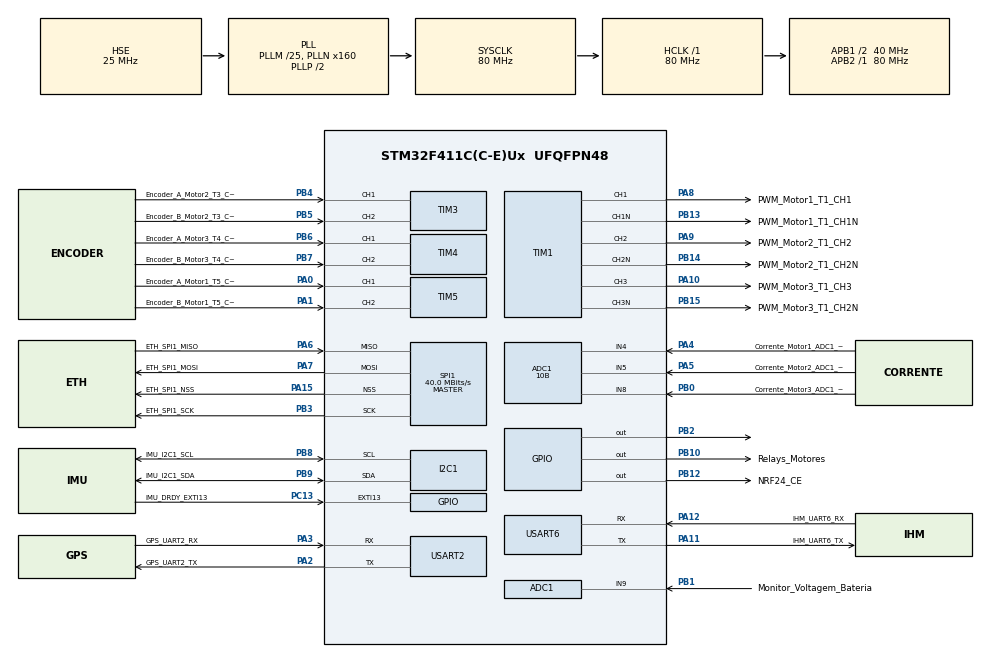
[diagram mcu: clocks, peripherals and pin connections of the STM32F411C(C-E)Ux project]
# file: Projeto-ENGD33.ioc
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ADC1.Channel-0\#ChannelRegularConversion=ADC_CHANNEL_4
ADC1.NbrOfConversion=1
ADC1.NbrOfConversionFlag=1
ADC1.Rank-0\#ChannelRegularConversion=1
ADC1.Resolution=ADC_RESOLUTION_10B
ADC1.SamplingTime-0\#ChannelRegularConversion=ADC_SAMPLETIME_3CYCLES
ADC1.master=1
FATFS._MAX_SS=4096
FREERTOS.Tasks01=defaultTask,24,128,StartDefaultTask,Default,NULL,Dynamic,NULL,NULL
FREERTOS.configUSE_NEWLIB_REENTRANT=1
Mcu.Family=STM32F4
Mcu.Name=STM32F411C(C-E)Ux
Mcu.Package=UFQFPN48
NVIC.EXTI15_10_IRQn=true\:5\:0\:false\:false\:true\:true\:true\:true\:true
NVIC.I2C1_ER_IRQn=true\:5\:0\:false\:false\:true\:true\:true\:true\:true
NVIC.I2C1_EV_IRQn=true\:5\:0\:false\:false\:true\:true\:true\:true\:true
NVIC.PriorityGroup=NVIC_PRIORITYGROUP_4
NVIC.SPI1_IRQn=true\:5\:0\:false\:false\:true\:true\:true\:true\:true
NVIC.TIM2_IRQn=true\:15\:0\:false\:false\:true\:false\:false\:true\:true
NVIC.TimeBase=TIM2_IRQn
NVIC.TimeBaseIP=TIM2
NVIC.USART2_IRQn=true\:5\:0\:false\:false\:true\:true\:true\:true\:true
NVIC.USART6_IRQn=true\:5\:0\:false\:false\:true\:true\:true\:true\:true
PA0-WKUP.GPIO_Label=Encoder_A_Motor1_T5_CH1
PA0-WKUP.Signal=S_TIM5_CH1
PA1.GPIO_Label=Encoder_B_Motor1_T5_CH2
PA1.Signal=S_TIM5_CH2
PA10.GPIO_Label=PWM_Motor3_T1_CH3
PA10.Signal=S_TIM1_CH3
PA11.GPIO_Label=IHM_UART6_TX
PA11.Mode=Asynchronous
PA11.Signal=USART6_TX
PA12.GPIO_Label=IHM_UART6_RX
PA12.Mode=Asynchronous
PA12.Signal=USART6_RX
PA13.Signal=SYS_JTMS-SWDIO
PA14.Signal=SYS_JTCK-SWCLK
PA15.GPIO_Label=ETH_SPI1_NSS
PA15.Mode=NSS_Signal_Hard_Output
PA15.Signal=SPI1_NSS
PA2.GPIO_Label=GPS_UART2_TX
PA2.Mode=Asynchronous
PA2.Signal=USART2_TX
PA3.GPIO_Label=GPS_UART2_RX
PA3.Mode=Asynchronous
PA3.Signal=USART2_RX
PA4.GPIO_Label=Corrente_Motor1_ADC1_IN4
PA4.Signal=ADCx_IN4
PA5.GPIO_Label=Corrente_Motor2_ADC1_IN5
PA5.Signal=ADCx_IN5
PA6.GPIO_Label=ETH_SPI1_MISO
PA6.Mode=Full_Duplex_Master
PA6.Signal=SPI1_MISO
PA7.GPIO_Label=ETH_SPI1_MOSI
PA7.Mode=Full_Duplex_Master
PA7.Signal=SPI1_MOSI
PA8.GPIO_Label=PWM_Motor1_T1_CH1
PA8.Signal=S_TIM1_CH1
PA9.GPIO_Label=PWM_Motor2_T1_CH2
PA9.Signal=S_TIM1_CH2
PB0.GPIO_Label=Corrente_Motor3_ADC1_IN8
PB0.Signal=ADCx_IN8
PB1.GPIO_Label=Monitor_Voltagem_Bateria
PB1.Signal=ADCx_IN9
PB10.GPIO_Label=Relays_Motores
PB10.Signal=GPIO_Output
PB12.GPIO_Label=NRF24_CE
PB12.GPIO_Speed=GPIO_SPEED_FREQ_VERY_HIGH
PB12.Signal=GPIO_Output
PB13.GPIO_Label=PWM_Motor1_T1_CH1N
PB13.Mode=PWM Generation1 CH1 CH1N
PB13.Signal=TIM1_CH1N
PB14.GPIO_Label=PWM_Motor2_T1_CH2N
PB14.Mode=PWM Generation2 CH2 CH2N
PB14.Signal=TIM1_CH2N
PB15.GPIO_Label=PWM_Motor3_T1_CH2N
PB15.Mode=PWM Generation3 CH3 CH3N
PB15.Signal=TIM1_CH3N
PB2.Signal=GPIO_Output
PB3.GPIO_Label=ETH_SPI1_SCK
PB3.Mode=Full_Duplex_Master
PB3.Signal=SPI1_SCK
PB4.GPIO_Label=Encoder_A_Motor2_T3_CH1
PB4.Signal=S_TIM3_CH1
PB5.GPIO_Label=Encoder_B_Motor2_T3_CH2
PB5.Signal=S_TIM3_CH2
PB6.GPIO_Label=Encoder_A_Motor3_T4_CH1
PB6.Signal=S_TIM4_CH1
PB7.GPIO_Label=Encoder_B_Motor3_T4_CH2
PB7.Signal=S_TIM4_CH2
PB8.GPIO_Label=IMU_I2C1_SCL
PB8.Mode=I2C
PB8.Signal=I2C1_SCL
PB9.GPIO_Label=IMU_I2C1_SDA
PB9.Mode=I2C
PB9.Signal=I2C1_SDA
PC13-ANTI_TAMP.GPIO_Label=IMU_DRDY_EXTI13
PC13-ANTI_TAMP.Signal=GPXTI13
PC14-OSC32_IN.GPIO_Label=Osc_32k768Hz_In
PC14-OSC32_IN.Mode=LSE-External-Oscillator
PC14-OSC32_IN.Signal=RCC_OSC32_IN
PC15-OSC32_OUT.GPIO_Label=Osc_32k768Hz_Out
PC15-OSC32_OUT.Mode=LSE-External-Oscillator
PC15-OSC32_OUT.Signal=RCC_OSC32_OUT
PH0\ -\ OSC_IN.GPIO_Label=Osc_25MHz_In
PH0\ -\ OSC_IN.Mode=HSE-External-Oscillator
PH0\ -\ OSC_IN.Signal=RCC_OSC_IN
PH1\ -\ OSC_OUT.GPIO_Label=Osc_25MHz_Out
PH1\ -\ OSC_OUT.Mode=HSE-External-Oscillator
PH1\ -\ OSC_OUT.Signal=RCC_OSC_OUT
ProjectManager.HeapSize=0x200
ProjectManager.StackSize=0x400
ProjectManager.TargetToolchain=STM32CubeIDE
RCC.48MHZClocksFreq_Value=40000000
RCC.AHBFreq_Value=80000000
RCC.APB1CLKDivider=RCC_HCLK_DIV2
RCC.APB1Freq_Value=40000000
RCC.APB1TimFreq_Value=80000000
RCC.APB2Freq_Value=80000000
RCC.APB2TimFreq_Value=80000000
RCC.CortexFreq_Value=80000000
RCC.HCLKFreq_Value=80000000
RCC.HSE_VALUE=25000000
RCC.HSI_VALUE=16000000
RCC.PLLM=25
RCC.PLLN=160
RCC.PLLSourceVirtual=RCC_PLLSOURCE_HSE
RCC.RCC_RTC_Clock_Source=RCC_RTCCLKSOURCE_LSE
RCC.RCC_RTC_Clock_SourceVirtual=RCC_RTCCLKSOURCE_LSE
RCC.SYSCLKFreq_VALUE=80000000
RCC.SYSCLKSource=RCC_SYSCLKSOURCE_PLLCLK
RCC.VCOOutputFreq_Value=160000000
SH.ADCx_IN4.0=ADC1_IN4,IN4
SH.ADCx_IN5.0=ADC1_IN5,IN5
SH.ADCx_IN8.0=ADC1_IN8,IN8
SH.ADCx_IN9.0=ADC1_IN9,IN9
SH.S_TIM1_CH1.0=TIM1_CH1,PWM Generation1 CH1 CH1N
SH.S_TIM1_CH2.0=TIM1_CH2,PWM Generation2 CH2 CH2N
SH.S_TIM1_CH3.0=TIM1_CH3,PWM Generation3 CH3 CH3N
SH.S_TIM3_CH1.0=TIM3_CH1,Encoder_Interface
SH.S_TIM3_CH2.0=TIM3_CH2,Encoder_Interface
SH.S_TIM4_CH1.0=TIM4_CH1,Encoder_Interface
SH.S_TIM4_CH2.0=TIM4_CH2,Encoder_Interface
SH.S_TIM5_CH1.0=TIM5_CH1,Encoder_Interface
SH.S_TIM5_CH2.0=TIM5_CH2,Encoder_Interface
SPI1.CalculateBaudRate=40.0 MBits/s
SPI1.Direction=SPI_DIRECTION_2LINES
SPI1.Mode=SPI_MODE_MASTER
SPI1.VirtualNSS=VM_NSSHARD
SPI1.VirtualType=VM_MASTER
TIM1.Channel-PWM\ Generation1\ CH1\ CH1N=TIM_CHANNEL_1
TIM1.Channel-PWM\ Generation2\ CH2\ CH2N=TIM_CHANNEL_2
TIM1.Channel-PWM\ Generation3\ CH3\ CH3N=TIM_CHANNEL_3
USART2.VirtualMode=VM_ASYNC
USART6.VirtualMode=VM_ASYNC
VP_ADC1_TempSens_Input.Mode=IN-TempSens
VP_FATFS_VS_Generic.Mode=User_defined
VP_FREERTOS_VS_CMSIS_V2.Mode=CMSIS_V2
VP_RTC_VS_RTC_Activate.Mode=RTC_Enabled
VP_RTC_VS_RTC_Calendar.Mode=RTC_Calendar
VP_SYS_VS_tim2.Mode=TIM2
VP_TIM1_VS_ClockSourceINT.Mode=Internal
board=custom

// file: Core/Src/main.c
/* USER CODE BEGIN Header */
/**
  ******************************************************************************
  * @file           : main.c
  * @brief          : Main program body
  ******************************************************************************
  * @attention
  *
  * Copyright (c) 2025 STMicroelectronics.
  * All rights reserved.
  *
  * This software is licensed under terms that can be found in the LICENSE file
  * in the root directory of this software component.
  * If no LICENSE file comes with this software, it is provided AS-IS.
  *
  ******************************************************************************
  */
/* USER CODE END Header */
#include "main.h"
#include "cmsis_os.h"
#include "fatfs.h"
#include "datalogger.h"

/* USER CODE BEGIN Includes */

#include "GY-87.h"
#include <math.h>
// Biblioteca necessária para o snprintf:
#include <stdio.h>
// FreeRTOS
#include "FreeRTOS.h"
#include "task.h"
#include "queue.h"
// #include <stdbool.h>

/* USER CODE END Includes */

ADC_HandleTypeDef hadc1;

I2C_HandleTypeDef hi2c1;

RTC_HandleTypeDef hrtc;

SPI_HandleTypeDef hspi1;

TIM_HandleTypeDef htim1;
TIM_HandleTypeDef htim3;
TIM_HandleTypeDef htim4;
TIM_HandleTypeDef htim5;

UART_HandleTypeDef huart2;
UART_HandleTypeDef huart6;

/* Definitions for defaultTask */
osThreadId_t defaultTaskHandle;
const osThreadAttr_t defaultTask_attributes = {
  .name = "defaultTask",
  .stack_size = 128 * 4,
  .priority = (osPriority_t) osPriorityNormal,
};

void SystemClock_Config(void);
static void MX_GPIO_Init(void);
static void MX_DMA_Init(void);
static void MX_RTC_Init(void);
static void MX_ADC1_Init(void);
static void MX_I2C1_Init(void);
static void MX_SPI1_Init(void);
static void MX_TIM1_Init(void);
static void MX_TIM3_Init(void);
static void MX_TIM4_Init(void);
static void MX_TIM5_Init(void);
static void MX_USART2_UART_Init(void);
static void MX_USART6_UART_Init(void);
void StartDefaultTask(void *argument);

/* USER CODE BEGIN PFP */
void HAL_GPIO_EXTI_Callback(uint16_t GPIO_Pin);
void HAL_TIM_PeriodElapsedCallback(TIM_HandleTypeDef* htim);
// void Calibrate_ADC_Converter(void);
void Start_Encoders(void);
void Stop_Encoders(void);
void Start_PWMs(void);
void Stop_PWMs(void);
void Reset_Relays_Motors(void);
void Set_Relays_Motors(void);
void Reset_NRF24_CE(void);
void Set_NRF24_CE(void);
void Configure_Compass(void);
int  Get_Direction_Rotation_Wheel_1(void);
int  Get_Direction_Rotation_Wheel_2(void);
int  Get_Direction_Rotation_Wheel_3(void);
float Read_Speed_Wheel_1(void);
float Read_Speed_Wheel_2(void);
float Read_Speed_Wheel_3(void);
float Read_Current_Motor_1(void);
float Read_Current_Motor_2(void);
float Read_Current_Motor_3(void);
void Write_Control_Signal_Motor_1(float Value);
void Write_Control_Signal_Motor_2(float Value);
void Write_Control_Signal_Motor_3(float Value);
float Read_Voltage_Battery(void);
float Read_Temperature_uP(void);
// Tasks do FreeRTOS
void Task_Controle(void *argument);
void Task_SDCard(void *argument);

// Funções de Hardware e Mock
TempoRTC_t Hardware_LerRTC(void);
Sensores_t Mock_LerSensores(void);

/* USER CODE END PFP */

int main(void)
{

  /* MCU Configuration--------------------------------------------------------*/

  /* Reset of all peripherals, Initializes the Flash interface and the Systick. */
  HAL_Init();

  /* Configure the system clock */
  SystemClock_Config();

  /* Initialize all configured peripherals */
  MX_GPIO_Init();
  MX_DMA_Init();
  MX_RTC_Init();
  MX_ADC1_Init();
  MX_I2C1_Init();
  MX_SPI1_Init();
  MX_TIM1_Init();
  MX_TIM3_Init();
  MX_TIM4_Init();
  MX_TIM5_Init();
  MX_USART2_UART_Init();
  MX_USART6_UART_Init();
  MX_FATFS_Init();
  /* USER CODE BEGIN 2 */
  Datalogger_Init();
  /* USER CODE END 2 */

  /* Init scheduler */
  osKernelInitialize();

  /* Create the thread(s) */
  /* creation of defaultTask */
  defaultTaskHandle = osThreadNew(StartDefaultTask, NULL, &defaultTask_attributes);

  /* Start scheduler */
  osKernelStart();

  /* We should never get here as control is now taken by the scheduler */

  /* Infinite loop */
  while (1)
  {

  }
}

void SystemClock_Config(void)
{
  RCC_OscInitTypeDef RCC_OscInitStruct = {0};
  RCC_ClkInitTypeDef RCC_ClkInitStruct = {0};

  /** Configure the main internal regulator output voltage
  */
  __HAL_RCC_PWR_CLK_ENABLE();
  __HAL_PWR_VOLTAGESCALING_CONFIG(PWR_REGULATOR_VOLTAGE_SCALE1);

  /** Initializes the RCC Oscillators according to the specified parameters
  * in the RCC_OscInitTypeDef structure.
  */
  RCC_OscInitStruct.OscillatorType = RCC_OSCILLATORTYPE_HSE|RCC_OSCILLATORTYPE_LSE;
  RCC_OscInitStruct.HSEState = RCC_HSE_ON;
  RCC_OscInitStruct.LSEState = RCC_LSE_ON;
  RCC_OscInitStruct.PLL.PLLState = RCC_PLL_ON;
  RCC_OscInitStruct.PLL.PLLSource = RCC_PLLSOURCE_HSE;
  RCC_OscInitStruct.PLL.PLLM = 25;
  RCC_OscInitStruct.PLL.PLLN = 160;
  RCC_OscInitStruct.PLL.PLLP = RCC_PLLP_DIV2;
  RCC_OscInitStruct.PLL.PLLQ = 4;
  if (HAL_RCC_OscConfig(&RCC_OscInitStruct) != HAL_OK)
  {
    Error_Handler();
  }

  /** Initializes the CPU, AHB and APB buses clocks
  */
  RCC_ClkInitStruct.ClockType = RCC_CLOCKTYPE_HCLK|RCC_CLOCKTYPE_SYSCLK
                              |RCC_CLOCKTYPE_PCLK1|RCC_CLOCKTYPE_PCLK2;
  RCC_ClkInitStruct.SYSCLKSource = RCC_SYSCLKSOURCE_PLLCLK;
  RCC_ClkInitStruct.AHBCLKDivider = RCC_SYSCLK_DIV1;
  RCC_ClkInitStruct.APB1CLKDivider = RCC_HCLK_DIV2;
  RCC_ClkInitStruct.APB2CLKDivider = RCC_HCLK_DIV1;

  if (HAL_RCC_ClockConfig(&RCC_ClkInitStruct, FLASH_LATENCY_2) != HAL_OK)
  {
    Error_Handler();
  }
}

static void MX_ADC1_Init(void)
{

  ADC_ChannelConfTypeDef sConfig = {0};

  /** Configure the global features of the ADC (Clock, Resolution, Data Alignment and number of conversion)
  */
  hadc1.Instance = ADC1;
  hadc1.Init.ClockPrescaler = ADC_CLOCK_SYNC_PCLK_DIV4;
  hadc1.Init.Resolution = ADC_RESOLUTION_10B;
  hadc1.Init.ScanConvMode = DISABLE;
  hadc1.Init.ContinuousConvMode = DISABLE;
  hadc1.Init.DiscontinuousConvMode = DISABLE;
  hadc1.Init.ExternalTrigConvEdge = ADC_EXTERNALTRIGCONVEDGE_NONE;
  hadc1.Init.ExternalTrigConv = ADC_SOFTWARE_START;
  hadc1.Init.DataAlign = ADC_DATAALIGN_RIGHT;
  hadc1.Init.NbrOfConversion = 1;
  hadc1.Init.DMAContinuousRequests = DISABLE;
  hadc1.Init.EOCSelection = ADC_EOC_SINGLE_CONV;
  if (HAL_ADC_Init(&hadc1) != HAL_OK)
  {
    Error_Handler();
  }

  /** Configure for the selected ADC regular channel its corresponding rank in the sequencer and its sample time.
  */
  sConfig.Channel = ADC_CHANNEL_4;
  sConfig.Rank = 1;
  sConfig.SamplingTime = ADC_SAMPLETIME_3CYCLES;
  if (HAL_ADC_ConfigChannel(&hadc1, &sConfig) != HAL_OK)
  {
    Error_Handler();
  }

}

static void MX_I2C1_Init(void)
{

  hi2c1.Instance = I2C1;
  hi2c1.Init.ClockSpeed = 400000;
  hi2c1.Init.DutyCycle = I2C_DUTYCYCLE_2;
  hi2c1.Init.OwnAddress1 = 0;
  hi2c1.Init.AddressingMode = I2C_ADDRESSINGMODE_7BIT;
  hi2c1.Init.DualAddressMode = I2C_DUALADDRESS_DISABLE;
  hi2c1.Init.OwnAddress2 = 0;
  hi2c1.Init.GeneralCallMode = I2C_GENERALCALL_DISABLE;
  hi2c1.Init.NoStretchMode = I2C_NOSTRETCH_DISABLE;
  if (HAL_I2C_Init(&hi2c1) != HAL_OK)
  {
    Error_Handler();
  }

}

static void MX_RTC_Init(void)
{

  RTC_TimeTypeDef sTime = {0};
  RTC_DateTypeDef sDate = {0};

  /** Initialize RTC Only
  */
  hrtc.Instance = RTC;
  hrtc.Init.HourFormat = RTC_HOURFORMAT_24;
  hrtc.Init.AsynchPrediv = 127;
  hrtc.Init.SynchPrediv = 255;
  hrtc.Init.OutPut = RTC_OUTPUT_DISABLE;
  hrtc.Init.OutPutPolarity = RTC_OUTPUT_POLARITY_HIGH;
  hrtc.Init.OutPutType = RTC_OUTPUT_TYPE_OPENDRAIN;
  if (HAL_RTC_Init(&hrtc) != HAL_OK)
  {
    Error_Handler();
  }

  /* USER CODE BEGIN Check_RTC_BKUP */

  /* Se a assinatura já estiver gravada no registrador de backup, o RTC
   * sobreviveu ao reset e já tem hora/data válidas: não sobrescrever. */
  if (HAL_RTCEx_BKUPRead(&hrtc, RTC_BKP_DR1) == 0x1234)
  {
    return;
  }

  /* USER CODE END Check_RTC_BKUP */

  /** Initialize RTC and set the Time and Date
  */
  sTime.Hours = 14;
  sTime.Minutes = 30;
  sTime.Seconds = 0;
  sTime.DayLightSaving = RTC_DAYLIGHTSAVING_NONE;
  sTime.StoreOperation = RTC_STOREOPERATION_RESET;
  if (HAL_RTC_SetTime(&hrtc, &sTime, RTC_FORMAT_BIN) != HAL_OK)
  {
    Error_Handler();
  }
  sDate.WeekDay = RTC_WEEKDAY_TUESDAY;
  sDate.Month = RTC_MONTH_JULY;
  sDate.Date = 7;
  sDate.Year = 26;

  if (HAL_RTC_SetDate(&hrtc, &sDate, RTC_FORMAT_BIN) != HAL_OK)
  {
    Error_Handler();
  }
  /* USER CODE BEGIN RTC_Init 2 */

  /* Marca no registrador de backup que a hora/data já foi configurada,
   * para não ser resetada nos próximos boots. */
  HAL_RTCEx_BKUPWrite(&hrtc, RTC_BKP_DR1, 0x1234);

  /* USER CODE END RTC_Init 2 */

}

static void MX_SPI1_Init(void)
{

  /* SPI1 parameter configuration*/
  hspi1.Instance = SPI1;
  hspi1.Init.Mode = SPI_MODE_MASTER;
  hspi1.Init.Direction = SPI_DIRECTION_2LINES;
  hspi1.Init.DataSize = SPI_DATASIZE_8BIT;
  hspi1.Init.CLKPolarity = SPI_POLARITY_LOW;
  hspi1.Init.CLKPhase = SPI_PHASE_1EDGE;
  hspi1.Init.NSS = SPI_NSS_HARD_OUTPUT;
  hspi1.Init.BaudRatePrescaler = SPI_BAUDRATEPRESCALER_2;
  hspi1.Init.FirstBit = SPI_FIRSTBIT_MSB;
  hspi1.Init.TIMode = SPI_TIMODE_DISABLE;
  hspi1.Init.CRCCalculation = SPI_CRCCALCULATION_DISABLE;
  hspi1.Init.CRCPolynomial = 10;
  if (HAL_SPI_Init(&hspi1) != HAL_OK)
  {
    Error_Handler();
  }

}

static void MX_TIM1_Init(void)
{

  TIM_ClockConfigTypeDef sClockSourceConfig = {0};
  TIM_MasterConfigTypeDef sMasterConfig = {0};
  TIM_OC_InitTypeDef sConfigOC = {0};
  TIM_BreakDeadTimeConfigTypeDef sBreakDeadTimeConfig = {0};

  htim1.Instance = TIM1;
  htim1.Init.Prescaler = 0;
  htim1.Init.CounterMode = TIM_COUNTERMODE_UP;
  htim1.Init.Period = 65535;
  htim1.Init.ClockDivision = TIM_CLOCKDIVISION_DIV1;
  htim1.Init.RepetitionCounter = 0;
  htim1.Init.AutoReloadPreload = TIM_AUTORELOAD_PRELOAD_DISABLE;
  if (HAL_TIM_Base_Init(&htim1) != HAL_OK)
  {
    Error_Handler();
  }
  sClockSourceConfig.ClockSource = TIM_CLOCKSOURCE_INTERNAL;
  if (HAL_TIM_ConfigClockSource(&htim1, &sClockSourceConfig) != HAL_OK)
  {
    Error_Handler();
  }
  if (HAL_TIM_PWM_Init(&htim1) != HAL_OK)
  {
    Error_Handler();
  }
  sMasterConfig.MasterOutputTrigger = TIM_TRGO_RESET;
  sMasterConfig.MasterSlaveMode = TIM_MASTERSLAVEMODE_DISABLE;
  if (HAL_TIMEx_MasterConfigSynchronization(&htim1, &sMasterConfig) != HAL_OK)
  {
    Error_Handler();
  }
  sConfigOC.OCMode = TIM_OCMODE_PWM1;
  sConfigOC.Pulse = 0;
  sConfigOC.OCPolarity = TIM_OCPOLARITY_HIGH;
  sConfigOC.OCNPolarity = TIM_OCNPOLARITY_HIGH;
  sConfigOC.OCFastMode = TIM_OCFAST_DISABLE;
  sConfigOC.OCIdleState = TIM_OCIDLESTATE_RESET;
  sConfigOC.OCNIdleState = TIM_OCNIDLESTATE_RESET;
  if (HAL_TIM_PWM_ConfigChannel(&htim1, &sConfigOC, TIM_CHANNEL_1) != HAL_OK)
  {
    Error_Handler();
  }
  if (HAL_TIM_PWM_ConfigChannel(&htim1, &sConfigOC, TIM_CHANNEL_2) != HAL_OK)
  {
    Error_Handler();
  }
  if (HAL_TIM_PWM_ConfigChannel(&htim1, &sConfigOC, TIM_CHANNEL_3) != HAL_OK)
  {
    Error_Handler();
  }
  sBreakDeadTimeConfig.OffStateRunMode = TIM_OSSR_DISABLE;
  sBreakDeadTimeConfig.OffStateIDLEMode = TIM_OSSI_DISABLE;
  sBreakDeadTimeConfig.LockLevel = TIM_LOCKLEVEL_OFF;
  sBreakDeadTimeConfig.DeadTime = 0;
  sBreakDeadTimeConfig.BreakState = TIM_BREAK_DISABLE;
  sBreakDeadTimeConfig.BreakPolarity = TIM_BREAKPOLARITY_HIGH;
  sBreakDeadTimeConfig.AutomaticOutput = TIM_AUTOMATICOUTPUT_DISABLE;
  if (HAL_TIMEx_ConfigBreakDeadTime(&htim1, &sBreakDeadTimeConfig) != HAL_OK)
  {
    Error_Handler();
  }
  HAL_TIM_MspPostInit(&htim1);

}

static void MX_TIM3_Init(void)
{

  TIM_Encoder_InitTypeDef sConfig = {0};
  TIM_MasterConfigTypeDef sMasterConfig = {0};

  htim3.Instance = TIM3;
  htim3.Init.Prescaler = 0;
  htim3.Init.CounterMode = TIM_COUNTERMODE_UP;
  htim3.Init.Period = 65535;
  htim3.Init.ClockDivision = TIM_CLOCKDIVISION_DIV1;
  htim3.Init.AutoReloadPreload = TIM_AUTORELOAD_PRELOAD_DISABLE;
  sConfig.EncoderMode = TIM_ENCODERMODE_TI12;
  sConfig.IC1Polarity = TIM_ICPOLARITY_RISING;
  sConfig.IC1Selection = TIM_ICSELECTION_DIRECTTI;
  sConfig.IC1Prescaler = TIM_ICPSC_DIV1;
  sConfig.IC1Filter = 0;
  sConfig.IC2Polarity = TIM_ICPOLARITY_RISING;
  sConfig.IC2Selection = TIM_ICSELECTION_DIRECTTI;
  sConfig.IC2Prescaler = TIM_ICPSC_DIV1;
  sConfig.IC2Filter = 0;
  if (HAL_TIM_Encoder_Init(&htim3, &sConfig) != HAL_OK)
  {
    Error_Handler();
  }
  sMasterConfig.MasterOutputTrigger = TIM_TRGO_RESET;
  sMasterConfig.MasterSlaveMode = TIM_MASTERSLAVEMODE_DISABLE;
  if (HAL_TIMEx_MasterConfigSynchronization(&htim3, &sMasterConfig) != HAL_OK)
  {
    Error_Handler();
  }

}

static void MX_TIM4_Init(void)
{

  TIM_Encoder_InitTypeDef sConfig = {0};
  TIM_MasterConfigTypeDef sMasterConfig = {0};

  htim4.Instance = TIM4;
  htim4.Init.Prescaler = 0;
  htim4.Init.CounterMode = TIM_COUNTERMODE_UP;
  htim4.Init.Period = 65535;
  htim4.Init.ClockDivision = TIM_CLOCKDIVISION_DIV1;
  htim4.Init.AutoReloadPreload = TIM_AUTORELOAD_PRELOAD_DISABLE;
  sConfig.EncoderMode = TIM_ENCODERMODE_TI1;
  sConfig.IC1Polarity = TIM_ICPOLARITY_RISING;
  sConfig.IC1Selection = TIM_ICSELECTION_DIRECTTI;
  sConfig.IC1Prescaler = TIM_ICPSC_DIV1;
  sConfig.IC1Filter = 0;
  sConfig.IC2Polarity = TIM_ICPOLARITY_RISING;
  sConfig.IC2Selection = TIM_ICSELECTION_DIRECTTI;
  sConfig.IC2Prescaler = TIM_ICPSC_DIV1;
  sConfig.IC2Filter = 0;
  if (HAL_TIM_Encoder_Init(&htim4, &sConfig) != HAL_OK)
  {
    Error_Handler();
  }
  sMasterConfig.MasterOutputTrigger = TIM_TRGO_RESET;
  sMasterConfig.MasterSlaveMode = TIM_MASTERSLAVEMODE_DISABLE;
  if (HAL_TIMEx_MasterConfigSynchronization(&htim4, &sMasterConfig) != HAL_OK)
  {
    Error_Handler();
  }

}

static void MX_TIM5_Init(void)
{

  TIM_Encoder_InitTypeDef sConfig = {0};
  TIM_MasterConfigTypeDef sMasterConfig = {0};

  htim5.Instance = TIM5;
  htim5.Init.Prescaler = 0;
  htim5.Init.CounterMode = TIM_COUNTERMODE_UP;
  htim5.Init.Period = 4294967295;
  htim5.Init.ClockDivision = TIM_CLOCKDIVISION_DIV1;
  htim5.Init.AutoReloadPreload = TIM_AUTORELOAD_PRELOAD_DISABLE;
  sConfig.EncoderMode = TIM_ENCODERMODE_TI1;
  sConfig.IC1Polarity = TIM_ICPOLARITY_RISING;
  sConfig.IC1Selection = TIM_ICSELECTION_DIRECTTI;
  sConfig.IC1Prescaler = TIM_ICPSC_DIV1;
  sConfig.IC1Filter = 0;
  sConfig.IC2Polarity = TIM_ICPOLARITY_RISING;
  sConfig.IC2Selection = TIM_ICSELECTION_DIRECTTI;
  sConfig.IC2Prescaler = TIM_ICPSC_DIV1;
  sConfig.IC2Filter = 0;
  if (HAL_TIM_Encoder_Init(&htim5, &sConfig) != HAL_OK)
  {
    Error_Handler();
  }
  sMasterConfig.MasterOutputTrigger = TIM_TRGO_RESET;
  sMasterConfig.MasterSlaveMode = TIM_MASTERSLAVEMODE_DISABLE;
  if (HAL_TIMEx_MasterConfigSynchronization(&htim5, &sMasterConfig) != HAL_OK)
  {
    Error_Handler();
  }

}

static void MX_USART2_UART_Init(void)
{

  huart2.Instance = USART2;
  huart2.Init.BaudRate = 115200;
  huart2.Init.WordLength = UART_WORDLENGTH_8B;
  huart2.Init.StopBits = UART_STOPBITS_1;
  huart2.Init.Parity = UART_PARITY_NONE;
  huart2.Init.Mode = UART_MODE_TX_RX;
  huart2.Init.HwFlowCtl = UART_HWCONTROL_NONE;
  huart2.Init.OverSampling = UART_OVERSAMPLING_16;
  if (HAL_UART_Init(&huart2) != HAL_OK)
  {
    Error_Handler();
  }

}

static void MX_USART6_UART_Init(void)
{

  huart6.Instance = USART6;
  huart6.Init.BaudRate = 115200;
  huart6.Init.WordLength = UART_WORDLENGTH_8B;
  huart6.Init.StopBits = UART_STOPBITS_1;
  huart6.Init.Parity = UART_PARITY_NONE;
  huart6.Init.Mode = UART_MODE_TX_RX;
  huart6.Init.HwFlowCtl = UART_HWCONTROL_NONE;
  huart6.Init.OverSampling = UART_OVERSAMPLING_16;
  if (HAL_UART_Init(&huart6) != HAL_OK)
  {
    Error_Handler();
  }

}

static void MX_DMA_Init(void)
{

  /* DMA controller clock enable */
  __HAL_RCC_DMA1_CLK_ENABLE();

  /* DMA interrupt init */
  /* DMA1_Stream5_IRQn interrupt configuration */
  HAL_NVIC_SetPriority(DMA1_Stream5_IRQn, 0, 0);
  HAL_NVIC_EnableIRQ(DMA1_Stream5_IRQn);
  /* DMA1_Stream6_IRQn interrupt configuration */
  HAL_NVIC_SetPriority(DMA1_Stream6_IRQn, 5, 0);
  HAL_NVIC_EnableIRQ(DMA1_Stream6_IRQn);

}

static void MX_GPIO_Init(void)
{
  GPIO_InitTypeDef GPIO_InitStruct = {0};
  /* USER CODE BEGIN MX_GPIO_Init_1 */

  /*Configure GPIO pin : Corrente_Motor1_ADC1_IN4_Pin */
  GPIO_InitStruct.Pin = Corrente_Motor1_ADC1_IN4_Pin;
  GPIO_InitStruct.Mode = GPIO_MODE_ANALOG;
  HAL_GPIO_Init(Corrente_Motor1_ADC1_IN4_GPIO_Port, &GPIO_InitStruct);

  /*Configure GPIO pin : Corrente_Motor2_ADC1_IN5_Pin */
  GPIO_InitStruct.Pin = Corrente_Motor2_ADC1_IN5_Pin;
  GPIO_InitStruct.Mode = GPIO_MODE_ANALOG;
  HAL_GPIO_Init(Corrente_Motor2_ADC1_IN5_GPIO_Port, &GPIO_InitStruct);

  /*Configure GPIO pin : Corrente_Motor3_ADC1_IN8_Pin */
  GPIO_InitStruct.Pin = Corrente_Motor3_ADC1_IN8_Pin;
  GPIO_InitStruct.Mode = GPIO_MODE_ANALOG;
  HAL_GPIO_Init(Corrente_Motor3_ADC1_IN8_GPIO_Port, &GPIO_InitStruct);

   /*Configure GPIO pin : Monitor_Voltagem_Bateria_Pin */
   GPIO_InitStruct.Pin = Monitor_Voltagem_Bateria_Pin;
   GPIO_InitStruct.Mode = GPIO_MODE_ANALOG;
   HAL_GPIO_Init(Monitor_Voltagem_Bateria_GPIO_Port, &GPIO_InitStruct);

   /*Configure GPIO pins : Encoder_A_Motor1_T5_CH1_Pin */
   GPIO_InitStruct.Pin = Encoder_A_Motor1_T5_CH1_Pin;
   GPIO_InitStruct.Mode = GPIO_MODE_AF_PP;
   /*GPIO_InitStruct.Pull = GPIO_NOPULL;*/
   GPIO_InitStruct.Speed = GPIO_SPEED_FREQ_LOW;
   GPIO_InitStruct.Alternate = GPIO_AF2_TIM5;
   HAL_GPIO_Init(Encoder_A_Motor1_T5_CH1_GPIO_Port, &GPIO_InitStruct);

   /*Configure GPIO pins : Encoder_B_Motor1_T5_CH2_Pin  */
   GPIO_InitStruct.Pin = Encoder_B_Motor1_T5_CH2_Pin;
   GPIO_InitStruct.Mode = GPIO_MODE_AF_PP;
   /*GPIO_InitStruct.Pull = GPIO_NOPULL;*/
   GPIO_InitStruct.Speed = GPIO_SPEED_FREQ_LOW;
   GPIO_InitStruct.Alternate = GPIO_AF2_TIM5;
   HAL_GPIO_Init(Encoder_B_Motor1_T5_CH2_GPIO_Port, &GPIO_InitStruct);

   /*Configure GPIO pins : Encoder_A_Motor2_T3_CH1_Pin */
   GPIO_InitStruct.Pin = Encoder_A_Motor2_T3_CH1_Pin;
   GPIO_InitStruct.Mode = GPIO_MODE_AF_PP;
   /*GPIO_InitStruct.Pull = GPIO_NOPULL;*/
   GPIO_InitStruct.Speed = GPIO_SPEED_FREQ_LOW;
   GPIO_InitStruct.Alternate = GPIO_AF2_TIM3;
   HAL_GPIO_Init(Encoder_A_Motor2_T3_CH1_GPIO_Port, &GPIO_InitStruct);

   /*Configure GPIO pins : Encoder_B_Motor2_T3_CH2_Pin  */
   GPIO_InitStruct.Pin = Encoder_B_Motor2_T3_CH2_Pin;
   GPIO_InitStruct.Mode = GPIO_MODE_AF_PP;
   /*GPIO_InitStruct.Pull = GPIO_NOPULL;*/
   GPIO_InitStruct.Speed = GPIO_SPEED_FREQ_LOW;
   GPIO_InitStruct.Alternate = GPIO_AF2_TIM3;
   HAL_GPIO_Init(Encoder_B_Motor2_T3_CH2_GPIO_Port, &GPIO_InitStruct);

   /*Configure GPIO pins : Encoder_A_Motor3_T4_CH1_Pin */
   GPIO_InitStruct.Pin = Encoder_A_Motor3_T4_CH1_Pin;
   GPIO_InitStruct.Mode = GPIO_MODE_AF_PP;
   /*GPIO_InitStruct.Pull = GPIO_NOPULL;*/
   GPIO_InitStruct.Speed = GPIO_SPEED_FREQ_LOW;
   GPIO_InitStruct.Alternate = GPIO_AF2_TIM4;
   HAL_GPIO_Init(Encoder_A_Motor3_T4_CH1_GPIO_Port, &GPIO_InitStruct);

   /*Configure GPIO pins : Encoder_B_Motor3_T4_CH2_Pin  */
   GPIO_InitStruct.Pin = Encoder_B_Motor3_T4_CH2_Pin;
   GPIO_InitStruct.Mode = GPIO_MODE_AF_PP;
   /*GPIO_InitStruct.Pull = GPIO_NOPULL;*/
   GPIO_InitStruct.Speed = GPIO_SPEED_FREQ_LOW;
   GPIO_InitStruct.Alternate = GPIO_AF2_TIM4;
   HAL_GPIO_Init(Encoder_B_Motor3_T4_CH2_GPIO_Port, &GPIO_InitStruct);

   /*Configure GPIO pins : PWM_Motor1_T1_CH1N_Pin  */
   GPIO_InitStruct.Pin = PWM_Motor1_T1_CH1N_Pin;
   GPIO_InitStruct.Mode = GPIO_MODE_AF_PP;
   /*GPIO_InitStruct.Pull = GPIO_NOPULL;*/
   GPIO_InitStruct.Speed = GPIO_SPEED_FREQ_LOW;
   GPIO_InitStruct.Alternate = GPIO_AF1_TIM1;
   HAL_GPIO_Init(PWM_Motor1_T1_CH1N_GPIO_Port, &GPIO_InitStruct);

   /*Configure GPIO pins : PWM_Motor2_T1_CH2N_Pin   */
   GPIO_InitStruct.Pin = PWM_Motor2_T1_CH2N_Pin;
   GPIO_InitStruct.Mode = GPIO_MODE_AF_PP;
   /*GPIO_InitStruct.Pull = GPIO_NOPULL;*/
   GPIO_InitStruct.Speed = GPIO_SPEED_FREQ_LOW;
   GPIO_InitStruct.Alternate = GPIO_AF1_TIM1;
   HAL_GPIO_Init(PWM_Motor2_T1_CH2N_GPIO_Port, &GPIO_InitStruct);

   /*Configure GPIO pins : PWM_Motor3_T1_CH2N_Pin (Corrigido de CH2N para CH3N para casar com o main.h) */
   GPIO_InitStruct.Pin = PWM_Motor3_T1_CH2N_Pin;
   GPIO_InitStruct.Mode = GPIO_MODE_AF_PP;
   /*GPIO_InitStruct.Pull = GPIO_NOPULL;*/
   GPIO_InitStruct.Speed = GPIO_SPEED_FREQ_LOW;
   GPIO_InitStruct.Alternate = GPIO_AF1_TIM1;
   HAL_GPIO_Init(PWM_Motor3_T1_CH2N_GPIO_Port, &GPIO_InitStruct);

   /*Configure GPIO pins : PWM_Motor1_T1_CH1_Pin  */
   GPIO_InitStruct.Pin = PWM_Motor1_T1_CH1_Pin;
   GPIO_InitStruct.Mode = GPIO_MODE_AF_PP;
   /*GPIO_InitStruct.Pull = GPIO_NOPULL;*/
   GPIO_InitStruct.Speed = GPIO_SPEED_FREQ_LOW;
   GPIO_InitStruct.Alternate = GPIO_AF1_TIM1;
   HAL_GPIO_Init(PWM_Motor1_T1_CH1_GPIO_Port, &GPIO_InitStruct);

   /*Configure GPIO pins : PWM_Motor2_T1_CH2_Pin   */
   GPIO_InitStruct.Pin = PWM_Motor2_T1_CH2_Pin;
   GPIO_InitStruct.Mode = GPIO_MODE_AF_PP;
   /*GPIO_InitStruct.Pull = GPIO_NOPULL;*/
   GPIO_InitStruct.Speed = GPIO_SPEED_FREQ_LOW;
   GPIO_InitStruct.Alternate = GPIO_AF1_TIM1;
   HAL_GPIO_Init(PWM_Motor2_T1_CH2_GPIO_Port, &GPIO_InitStruct);

   /*Configure GPIO pins : PWM_Motor3_T1_CH3_Pin   */
   GPIO_InitStruct.Pin = PWM_Motor3_T1_CH3_Pin;
   GPIO_InitStruct.Mode = GPIO_MODE_AF_PP;
   /*GPIO_InitStruct.Pull = GPIO_NOPULL;*/
   GPIO_InitStruct.Speed = GPIO_SPEED_FREQ_LOW;
   GPIO_InitStruct.Alternate = GPIO_AF1_TIM1;
   HAL_GPIO_Init(PWM_Motor3_T1_CH3_GPIO_Port, &GPIO_InitStruct);

   /*Configure GPIO pins : IMU_I2C1_SCL_Pin   */
   GPIO_InitStruct.Pin = IMU_I2C1_SCL_Pin;
   GPIO_InitStruct.Mode = GPIO_MODE_AF_PP;
   /*GPIO_InitStruct.Pull = GPIO_NOPULL;*/
   GPIO_InitStruct.Speed = GPIO_SPEED_FREQ_LOW;
   GPIO_InitStruct.Alternate = GPIO_AF4_I2C1;
   HAL_GPIO_Init(IMU_I2C1_SCL_GPIO_Port, &GPIO_InitStruct);

   /*Configure GPIO pins : IMU_I2C1_SDA_Pin   */
   GPIO_InitStruct.Pin = IMU_I2C1_SDA_Pin;
   GPIO_InitStruct.Mode = GPIO_MODE_AF_PP;
   /*GPIO_InitStruct.Pull = GPIO_NOPULL;*/
   GPIO_InitStruct.Speed = GPIO_SPEED_FREQ_LOW;
   GPIO_InitStruct.Alternate = GPIO_AF4_I2C1;
   HAL_GPIO_Init(IMU_I2C1_SDA_GPIO_Port, &GPIO_InitStruct);

   /*Configure GPIO pins : ETH_SPI1_NSS_Pin   */
   GPIO_InitStruct.Pin = ETH_SPI1_NSS_Pin;
   GPIO_InitStruct.Mode = GPIO_MODE_AF_PP;
   /*GPIO_InitStruct.Pull = GPIO_NOPULL;*/
   GPIO_InitStruct.Speed = GPIO_SPEED_FREQ_MEDIUM;
   GPIO_InitStruct.Alternate = GPIO_AF5_SPI1;
   HAL_GPIO_Init(ETH_SPI1_NSS_GPIO_Port, &GPIO_InitStruct);

   /*Configure GPIO pins : ETH_SPI1_SCK_Pin   */
   GPIO_InitStruct.Pin = ETH_SPI1_SCK_Pin;
   GPIO_InitStruct.Mode = GPIO_MODE_AF_PP;
   /*GPIO_InitStruct.Pull = GPIO_NOPULL;*/
   GPIO_InitStruct.Speed = GPIO_SPEED_FREQ_MEDIUM;
   GPIO_InitStruct.Alternate = GPIO_AF5_SPI1;
   HAL_GPIO_Init(ETH_SPI1_SCK_GPIO_Port, &GPIO_InitStruct);

   /*Configure GPIO pins : ETH_SPI1_MISO_Pin   */
   GPIO_InitStruct.Pin = ETH_SPI1_MISO_Pin;
   GPIO_InitStruct.Mode = GPIO_MODE_AF_PP;
   /*GPIO_InitStruct.Pull = GPIO_NOPULL;*/
   GPIO_InitStruct.Speed = GPIO_SPEED_FREQ_MEDIUM;
   GPIO_InitStruct.Alternate = GPIO_AF5_SPI1;
   HAL_GPIO_Init(ETH_SPI1_MISO_GPIO_Port, &GPIO_InitStruct);

   /*Configure GPIO pins : ETH_SPI1_MOSI_Pin   */
   GPIO_InitStruct.Pin = ETH_SPI1_MOSI_Pin;
   GPIO_InitStruct.Mode = GPIO_MODE_AF_PP;
   /*GPIO_InitStruct.Pull = GPIO_NOPULL;*/
   GPIO_InitStruct.Speed = GPIO_SPEED_FREQ_MEDIUM;
   GPIO_InitStruct.Alternate = GPIO_AF5_SPI1;
   HAL_GPIO_Init(ETH_SPI1_MOSI_GPIO_Port, &GPIO_InitStruct);

   /*Configure GPIO pins : IHM_UART6_TX_Pin   */
   GPIO_InitStruct.Pin = IHM_UART6_TX_Pin;
   GPIO_InitStruct.Mode = GPIO_MODE_AF_PP;
   /*GPIO_InitStruct.Pull = GPIO_NOPULL;*/
   GPIO_InitStruct.Speed = GPIO_SPEED_FREQ_LOW;
   GPIO_InitStruct.Alternate = GPIO_AF8_USART6;
   HAL_GPIO_Init(IHM_UART6_TX_GPIO_Port, &GPIO_InitStruct);

   /*Configure GPIO pins : IHM_UART6_RX_Pin   */
   GPIO_InitStruct.Pin = IHM_UART6_RX_Pin;
   GPIO_InitStruct.Mode = GPIO_MODE_AF_PP;
   /*GPIO_InitStruct.Pull = GPIO_NOPULL;*/
   GPIO_InitStruct.Speed = GPIO_SPEED_FREQ_LOW;
   GPIO_InitStruct.Alternate = GPIO_AF8_USART6;
   HAL_GPIO_Init(IHM_UART6_RX_GPIO_Port, &GPIO_InitStruct);

   /*Configure GPIO pins : GPS_UART2_TX_Pin   */
   GPIO_InitStruct.Pin = GPS_UART2_TX_Pin;
   GPIO_InitStruct.Mode = GPIO_MODE_AF_PP;
   /*GPIO_InitStruct.Pull = GPIO_NOPULL;*/
   GPIO_InitStruct.Speed = GPIO_SPEED_FREQ_LOW;
   GPIO_InitStruct.Alternate = GPIO_AF7_USART2;
   HAL_GPIO_Init(GPS_UART2_TX_GPIO_Port, &GPIO_InitStruct);

   /*Configure GPIO pins : GPS_UART2_RX_Pin   */
   GPIO_InitStruct.Pin = GPS_UART2_RX_Pin;
   GPIO_InitStruct.Mode = GPIO_MODE_AF_PP;
   /*GPIO_InitStruct.Pull = GPIO_NOPULL;*/
   GPIO_InitStruct.Speed = GPIO_SPEED_FREQ_LOW;
   GPIO_InitStruct.Alternate = GPIO_AF7_USART2;
   HAL_GPIO_Init(GPS_UART2_RX_GPIO_Port, &GPIO_InitStruct);

  /* USER CODE END MX_GPIO_Init_1 */

  /* GPIO Ports Clock Enable */
  __HAL_RCC_GPIOC_CLK_ENABLE();
  __HAL_RCC_GPIOH_CLK_ENABLE();
  __HAL_RCC_GPIOA_CLK_ENABLE();
  __HAL_RCC_GPIOB_CLK_ENABLE();

  /*Configure GPIO pin Output Level */
  HAL_GPIO_WritePin(GPIOB, SD_CS_Pin|Relays_Motores_Pin|NRF24_CE_Pin, GPIO_PIN_RESET);

  /*Configure GPIO pin : IMU_DRDY_EXTI13_Pin */
  GPIO_InitStruct.Pin = IMU_DRDY_EXTI13_Pin;
  GPIO_InitStruct.Mode = GPIO_MODE_IT_RISING;
  GPIO_InitStruct.Pull = GPIO_NOPULL;
  HAL_GPIO_Init(IMU_DRDY_EXTI13_GPIO_Port, &GPIO_InitStruct);

  /*Configure GPIO pins : SD_CS_Pin Relays_Motores_Pin */
  GPIO_InitStruct.Pin = SD_CS_Pin|Relays_Motores_Pin;
  GPIO_InitStruct.Mode = GPIO_MODE_OUTPUT_PP;
  GPIO_InitStruct.Pull = GPIO_NOPULL;
  GPIO_InitStruct.Speed = GPIO_SPEED_FREQ_LOW;
  HAL_GPIO_Init(GPIOB, &GPIO_InitStruct);

  /*Configure GPIO pin : NRF24_CE_Pin */
  GPIO_InitStruct.Pin = NRF24_CE_Pin;
  GPIO_InitStruct.Mode = GPIO_MODE_OUTPUT_PP;
  GPIO_InitStruct.Pull = GPIO_NOPULL;
  GPIO_InitStruct.Speed = GPIO_SPEED_FREQ_VERY_HIGH;
  HAL_GPIO_Init(NRF24_CE_GPIO_Port, &GPIO_InitStruct);

  /* EXTI interrupt init*/
  HAL_NVIC_SetPriority(EXTI15_10_IRQn, 5, 0);
  HAL_NVIC_EnableIRQ(EXTI15_10_IRQn);

}

/* USER CODE BEGIN 4 */

// External Interrupt ISR Handler CallBackFun
void HAL_GPIO_EXTI_Callback(uint16_t GPIO_Pin)
{
    // Corrigido: Substituído IMU_DRDY_EXTI13_Pin por IMU_DRDY_EXTI13_Pin
    if(GPIO_Pin == IMU_DRDY_EXTI13_Pin)
    {
    // HAL_GPIO_TogglePin(GPIOA, GPIO_PIN_11); // Toggle LED
    }
}

void Start_Encoders(void)
{
	HAL_TIM_Encoder_Start(&htim3, TIM_CHANNEL_ALL);
	HAL_TIM_Encoder_Start(&htim4, TIM_CHANNEL_ALL);
	HAL_TIM_Encoder_Start(&htim5, TIM_CHANNEL_ALL);
	// Corrigido: Passando ponteiros (&htimX) para as macros do HAL
	__HAL_TIM_SET_COUNTER(&htim3,0);
	__HAL_TIM_SET_COUNTER(&htim4,0);
	__HAL_TIM_SET_COUNTER(&htim5,0);
}

void Stop_Encoders(void)
{
	HAL_TIM_Encoder_Stop(&htim3, TIM_CHANNEL_ALL);
	HAL_TIM_Encoder_Stop(&htim4, TIM_CHANNEL_ALL);
	HAL_TIM_Encoder_Stop(&htim5, TIM_CHANNEL_ALL);
}

void Start_PWMs(void)
{
	HAL_TIM_PWM_Init(&htim1);
	HAL_TIM_PWM_Start(&htim1, TIM_CHANNEL_1);
	__HAL_TIM_SET_COMPARE(&htim1, TIM_CHANNEL_1, 250);
	HAL_TIM_PWM_Start(&htim1, TIM_CHANNEL_2);
	__HAL_TIM_SET_COMPARE(&htim1, TIM_CHANNEL_2, 250);
	HAL_TIM_PWM_Start(&htim1, TIM_CHANNEL_3);
	__HAL_TIM_SET_COMPARE(&htim1, TIM_CHANNEL_3, 250);
}

void Stop_PWMs(void)
{
	__HAL_TIM_SET_COMPARE(&htim1, TIM_CHANNEL_1, 250);
	__HAL_TIM_SET_COMPARE(&htim1, TIM_CHANNEL_2, 250);
	__HAL_TIM_SET_COMPARE(&htim1, TIM_CHANNEL_3, 250);
	HAL_TIM_PWM_Stop(&htim1, TIM_CHANNEL_1);
	HAL_TIM_PWM_Stop(&htim1, TIM_CHANNEL_2);
	HAL_TIM_PWM_Stop(&htim1, TIM_CHANNEL_3);
	HAL_TIM_PWM_DeInit(&htim1);
}

void Reset_Relays_Motors(void)
{
	HAL_GPIO_WritePin(GPIOB, Relays_Motores_Pin, GPIO_PIN_RESET);
}

void Set_Relays_Motors(void)
{
	HAL_GPIO_WritePin(GPIOB, Relays_Motores_Pin, GPIO_PIN_SET);
}

void Reset_NRF24_CE(void)
{
	HAL_GPIO_WritePin(GPIOB, NRF24_CE_Pin, GPIO_PIN_RESET);
}

void Set_NRF24_CE(void)
{
	HAL_GPIO_WritePin(GPIOB, NRF24_CE_Pin, GPIO_PIN_SET);
}

int  Get_Direction_Rotation_Wheel_1(void)
{
	int direction = 0;
	direction = __HAL_TIM_IS_TIM_COUNTING_DOWN(&htim5);
	return direction;
}

float Read_Speed_Wheel_1(void)
{
	int new_value_counter = 0;
	float speed_rotational = 0;

	// Corrigido: Passando ponteiros (&htim5)
	new_value_counter = __HAL_TIM_GET_COUNTER(&htim5);
	__HAL_TIM_SET_COUNTER(&htim5,0);
	speed_rotational = ((float)new_value_counter)/36.0f;
	return speed_rotational;
}

float Read_Speed_Wheel_2(void)
{
	int new_value_counter = 0;
	float speed_rotational = 0;

	// Corrigido: Passando ponteiros (&htim3)
	new_value_counter = __HAL_TIM_GET_COUNTER(&htim3);
	__HAL_TIM_SET_COUNTER(&htim3,0);
	speed_rotational = ((float)new_value_counter)/36.0f;
	return speed_rotational;
}

float Read_Speed_Wheel_3(void)
{
	int new_value_counter = 0;
	float speed_rotational = 0;

	// Corrigido: Passando ponteiros (&htim4)
	new_value_counter = __HAL_TIM_GET_COUNTER(&htim4);
	__HAL_TIM_SET_COUNTER(&htim4,0);
	speed_rotational = ((float)new_value_counter)/36.0f;
	return speed_rotational;
}

float Read_Current_Motor_1(void)
{
	float corrente;
	uint16_t Value;
	ADC_ChannelConfTypeDef sConfig;

	sConfig.Channel = ADC_CHANNEL_4;
	sConfig.Rank = 1;
	sConfig.SamplingTime = ADC_SAMPLETIME_112CYCLES;
	if (HAL_ADC_ConfigChannel(&hadc1, &sConfig) != HAL_OK)
	{
	   Error_Handler();
	}
	HAL_ADC_Start(&hadc1);
	HAL_ADC_PollForConversion(&hadc1, 1);
	Value = HAL_ADC_GetValue(&hadc1);
	HAL_ADC_Stop(&hadc1);
	corrente =   ((((float) Value)/1024.0f) - 0.5) * 30;
	return corrente;
}

float Read_Current_Motor_2(void)
{
	float corrente;
	uint16_t Value;
	ADC_ChannelConfTypeDef sConfig;

	sConfig.Channel = ADC_CHANNEL_5;
	sConfig.Rank = 1;
	sConfig.SamplingTime = ADC_SAMPLETIME_112CYCLES;
	if (HAL_ADC_ConfigChannel(&hadc1, &sConfig) != HAL_OK)
	{
	   Error_Handler();
	}
	HAL_ADC_Start(&hadc1);
	HAL_ADC_PollForConversion(&hadc1, 1);
	Value = HAL_ADC_GetValue(&hadc1);
	HAL_ADC_Stop(&hadc1);
	corrente =   ((((float) Value)/1024.0f) - 0.5) * 30;
	return corrente;
}

float Read_Current_Motor_3(void)
{
	float corrente;
	uint16_t Value;
	ADC_ChannelConfTypeDef sConfig;

	sConfig.Channel = ADC_CHANNEL_8;
	sConfig.Rank = 1;
	sConfig.SamplingTime = ADC_SAMPLETIME_112CYCLES;
	if (HAL_ADC_ConfigChannel(&hadc1, &sConfig) != HAL_OK)
	{
	   Error_Handler();
	}
	HAL_ADC_Start(&hadc1);
	HAL_ADC_PollForConversion(&hadc1, 1);
	Value = HAL_ADC_GetValue(&hadc1);
	HAL_ADC_Stop(&hadc1);
	corrente =   ((((float) Value)/1024.0f) - 0.5) * 30;
	return corrente;
}

void Write_Control_Signal_Motor_1(float Value)
{
	float input = Value;
	float aux = 0;
	uint16_t pw = 0;

	if ((input >= (-1.0f)) && (input <= 1.0f))
	{
		aux = ((Value*240.0f) + 250.0f);
		pw = ((uint16_t) aux);
		__HAL_TIM_SET_COMPARE(&htim1, TIM_CHANNEL_1, pw);
	}else
	{
		if (input > 1.0f)
		{
			__HAL_TIM_SET_COMPARE(&htim1, TIM_CHANNEL_1, 490);
		}
		else
		{
			if (input < (-1.0f))
			{
				__HAL_TIM_SET_COMPARE(&htim1, TIM_CHANNEL_1, 10);
			}
		}
	}
}

void Write_Control_Signal_Motor_2(float Value)
{
	float input = Value;
	float aux = 0;
	uint16_t pw = 0;

	if ((input >= (-1.0f)) && (input <= 1.0f))
	{
		aux = ((Value*240.0f) + 250.0f);
		pw = ((uint16_t) aux);
		__HAL_TIM_SET_COMPARE(&htim1, TIM_CHANNEL_2, pw);
	}else
	{
		if (input > 1.0f)
		{
			__HAL_TIM_SET_COMPARE(&htim1, TIM_CHANNEL_2, 490);
		}
		else
		{
			if (input < (-1.0f))
			{
				__HAL_TIM_SET_COMPARE(&htim1, TIM_CHANNEL_2, 10);
			}
		}
	}
}

void Write_Control_Signal_Motor_3(float Value)
{
	float input = Value;
	float aux = 0;
	uint16_t pw = 0;

	if ((input >= (-1.0f)) && (input <= 1.0f))
	{
		aux = ((Value*240.0f) + 250.0f);
		pw = ((uint16_t) aux);
		__HAL_TIM_SET_COMPARE(&htim1, TIM_CHANNEL_3, pw);
	}else
	{
		if (input > 1.0f)
		{
			__HAL_TIM_SET_COMPARE(&htim1, TIM_CHANNEL_3, 490);
		}
		else
		{
			if (input < (-1.0f))
			{
				__HAL_TIM_SET_COMPARE(&htim1, TIM_CHANNEL_3, 10);
			}
		}
	}
}

float Read_Voltage_Battery(void)
{
	float voltagem;
	uint16_t Value;;
	ADC_ChannelConfTypeDef sConfig;

	sConfig.Channel = ADC_CHANNEL_9;
	sConfig.Rank = 1;
	sConfig.SamplingTime = ADC_SAMPLETIME_112CYCLES;
	if (HAL_ADC_ConfigChannel(&hadc1, &sConfig) != HAL_OK)
	{
	   Error_Handler();
	}
	HAL_ADC_Start(&hadc1);
	HAL_ADC_PollForConversion(&hadc1, 1);
	Value = HAL_ADC_GetValue(&hadc1);
	HAL_ADC_Stop(&hadc1);
	voltagem =   (((float) Value)/1024.0f) * 15.0f;
	return voltagem;
}

float Read_Temperature_uP(void)
{
	uint16_t Value;
	float voltagem_sensor, temperatura;
	ADC_ChannelConfTypeDef sConfig;

	sConfig.Channel = ADC_CHANNEL_TEMPSENSOR;
	sConfig.Rank = 1;
	sConfig.SamplingTime = ADC_SAMPLETIME_112CYCLES;
	if (HAL_ADC_ConfigChannel(&hadc1, &sConfig) != HAL_OK)
	{
	   Error_Handler();
	}
	HAL_ADC_Start(&hadc1);
	HAL_ADC_PollForConversion(&hadc1, 1);
	Value = HAL_ADC_GetValue(&hadc1);
	HAL_ADC_Stop(&hadc1);
	voltagem_sensor =  ((((float) Value)*3.3)/1024.0f);
	temperatura = ((voltagem_sensor - 0.76)/0.0025) + 25.0f;
	return temperatura;
}

/* USER CODE END 4 */

void StartDefaultTask(void *argument)
{
  for(;;)
  {
    osDelay(1);
  }
}

void HAL_TIM_PeriodElapsedCallback(TIM_HandleTypeDef *htim)
{
  if (htim->Instance == TIM2)
  {
    HAL_IncTick();
  }
}

void Error_Handler(void)
{
  __disable_irq();
  while (1)
  {
  }
}
